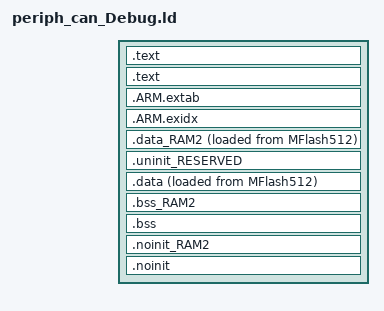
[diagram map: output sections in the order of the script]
/*
 * GENERATED FILE - DO NOT EDIT
 * (c) Code Red Technologies Ltd, 2008-2013
 * (c) NXP Semiconductors 2013-2016
 * Generated linker script file for LPC1788
 * Created from linkscript.ldt by FMCreateLinkLibraries
 * Using Freemarker v2.3.23
 * LPCXpresso v8.0.0 [Build 526] [2015-11-23]  on 17 mai 2016 08:37:14
 */

INCLUDE "periph_can_Debug_library.ld"
INCLUDE "periph_can_Debug_memory.ld"

ENTRY(ResetISR)

SECTIONS
{
    /* MAIN TEXT SECTION */
    .text : ALIGN(4)
    {
        FILL(0xff)
        __vectors_start__ = ABSOLUTE(.) ;
        KEEP(*(.isr_vector))
        /* Global Section Table */
        . = ALIGN(4) ; 
        __section_table_start = .;
        __data_section_table = .;
        LONG(LOADADDR(.data));
        LONG(    ADDR(.data));
        LONG(  SIZEOF(.data));
        LONG(LOADADDR(.data_RAM2));
        LONG(    ADDR(.data_RAM2));
        LONG(  SIZEOF(.data_RAM2));
        __data_section_table_end = .;
        __bss_section_table = .;
        LONG(    ADDR(.bss));
        LONG(  SIZEOF(.bss));
        LONG(    ADDR(.bss_RAM2));
        LONG(  SIZEOF(.bss_RAM2));
        __bss_section_table_end = .;
        __section_table_end = . ;
	    /* End of Global Section Table */

        *(.after_vectors*)

    } >MFlash512

    .text : ALIGN(4)    
    {
        *(.text*)
        *(.rodata .rodata.* .constdata .constdata.*)
        . = ALIGN(4);
    } > MFlash512
    /*
     * for exception handling/unwind - some Newlib functions (in common
     * with C++ and STDC++) use this. 
     */
    .ARM.extab : ALIGN(4) 
    {
        *(.ARM.extab* .gnu.linkonce.armextab.*)
    } > MFlash512
    __exidx_start = .;

    .ARM.exidx : ALIGN(4)
    {
        *(.ARM.exidx* .gnu.linkonce.armexidx.*)
    } > MFlash512
    __exidx_end = .;

    _etext = .;
        
    /* DATA section for RamPeriph32 */
    .data_RAM2 : ALIGN(4)
    {
        FILL(0xff)
        PROVIDE(__start_data_RAM2 = .) ;
        *(.ramfunc.$RAM2)
        *(.ramfunc.$RamPeriph32)
        *(.data.$RAM2*)
        *(.data.$RamPeriph32*)
        . = ALIGN(4) ;
        PROVIDE(__end_data_RAM2 = .) ;
     } > RamPeriph32 AT>MFlash512

    /* MAIN DATA SECTION */
    .uninit_RESERVED : ALIGN(4)
    {
        KEEP(*(.bss.$RESERVED*))
        . = ALIGN(4) ;
        _end_uninit_RESERVED = .;
    } > RamLoc64
    /* Main DATA section (RamLoc64) */
    .data : ALIGN(4)
    {
       FILL(0xff)
       _data = . ;
       *(vtable)
       *(.ramfunc*)
       *(.data*)
       . = ALIGN(4) ;
       _edata = . ;
    } > RamLoc64 AT>MFlash512
    /* BSS section for RamPeriph32 */
    .bss_RAM2 : ALIGN(4)
    {
       PROVIDE(__start_bss_RAM2 = .) ;
       *(.bss.$RAM2*)
       *(.bss.$RamPeriph32*)
       . = ALIGN (. != 0 ? 4 : 1) ; /* avoid empty segment */
       PROVIDE(__end_bss_RAM2 = .) ;
    } > RamPeriph32 
    /* MAIN BSS SECTION */
    .bss : ALIGN(4)
    {
        _bss = .;
        *(.bss*)
        *(COMMON)
        . = ALIGN(4) ;
        _ebss = .;
        PROVIDE(end = .);
    } > RamLoc64
    /* NOINIT section for RamPeriph32 */
    .noinit_RAM2 (NOLOAD) : ALIGN(4)
    {
       *(.noinit.$RAM2*)
       *(.noinit.$RamPeriph32*)
       . = ALIGN(4) ;
    } > RamPeriph32 
    /* DEFAULT NOINIT SECTION */
    .noinit (NOLOAD): ALIGN(4)
    {
        _noinit = .;
        *(.noinit*) 
         . = ALIGN(4) ;
        _end_noinit = .;
    } > RamLoc64

    PROVIDE(_pvHeapStart = DEFINED(__user_heap_base) ? __user_heap_base : .);
    PROVIDE(_vStackTop = DEFINED(__user_stack_top) ? __user_stack_top : __top_RamLoc64 - 0);

    /* ## Create checksum value (used in startup) ## */
    PROVIDE(__valid_user_code_checksum = 0 - 
                                         (_vStackTop 
                                         + (ResetISR + 1) 
                                         + (NMI_Handler + 1) 
                                         + (HardFault_Handler + 1) 
                                         + (( DEFINED(MemManage_Handler) ? MemManage_Handler : 0 ) + 1)   /* MemManage_Handler may not be defined */
                                         + (( DEFINED(BusFault_Handler) ? BusFault_Handler : 0 ) + 1)     /* BusFault_Handler may not be defined */
                                         + (( DEFINED(UsageFault_Handler) ? UsageFault_Handler : 0 ) + 1) /* UsageFault_Handler may not be defined */
                                         ) );
}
